# MKL17Z644 register map
Vendor: Freescale Semiconductor, Inc.; Series: Kinetis_L; File version: 1.6
CPU: CM0PLUS r0p0, little endian, no MPU, no FPU, VTOR, 2 interrupt priority bits
Registers are 32-bit, read-write, reset 0x0 unless marked. A register's access mark holds for its fields unless they carry their own. Offsets are from the block's base; [hi:lo] are bit positions; {n}, {i} and the like mark numbered series; 'fields as' and 'values as' point back to an identical list.

## RFSYS — System register file
Base 0x40041000; register names take the prefix RFSYS_
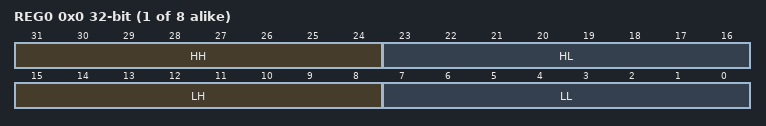
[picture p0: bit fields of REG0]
{0x0+4i} REG{i} (i=0..7) — Register file register
  [31:24] HH, [23:16] HL, [15:8] LH, [7:0] LL

## PORTA — Pin Control and Interrupts
Base 0x40049000; register names take the prefix PORTA_
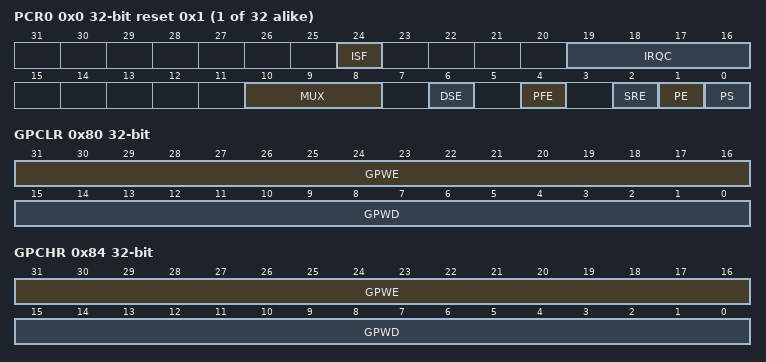
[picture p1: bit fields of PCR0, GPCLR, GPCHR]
{0x0+4i} PCR{i} (i=0..31) reset 0x1 — Pin Control Register n
  [24] ISF — Interrupt Status Flag
    0=Configured interrupt is not detected; 1=Configured interrupt is detected. If the pin is configured to generate a DMA request, then the corresponding flag will be cleared automatically at the completion of the requested DMA transfer. Otherwise, the flag remains set until a logic 1 is written to the flag. If the pin is configured for a level sensitive interrupt and the pin remains asserted, then the flag is set again immediately after it is cleared.
  [19:16] IRQC — Interrupt Configuration
    0=Flag is disabled; 1=Flag and DMA request on rising edge; 2=Flag and DMA request on falling edge; 3=Flag and DMA request on either edge; 8=Flag and Interrupt when logic 0; 9=Flag and Interrupt on rising-edge; 10=Flag and Interrupt on falling-edge; 11=Flag and Interrupt on either edge; 12=Flag and Interrupt when logic 1
  [10:8] MUX — Pin Mux Control
    0=Pin disabled (analog); 1=Alternative 1 (GPIO); {v}=Alternative {v} (chip-specific) (v=2..7)
  [6] DSE — Drive Strength Enable
    0=Low drive strength is configured on the corresponding pin, if pin is configured as a digital output; 1=High drive strength is configured on the corresponding pin, if pin is configured as a digital output
  [4] PFE — Passive Filter Enable
    0=Passive input filter is disabled on the corresponding pin; 1=Passive input filter is enabled on the corresponding pin, if the pin is configured as a digital input. Refer to the device data sheet for filter characteristics.
  [2] SRE — Slew Rate Enable
    0=Fast slew rate is configured on the corresponding pin, if the pin is configured as a digital output; 1=Slow slew rate is configured on the corresponding pin, if the pin is configured as a digital output
  [1] PE — Pull Enable
    0=Internal pullup or pulldown resistor is not enabled on the corresponding pin; 1=Internal pullup or pulldown resistor is enabled on the corresponding pin, if the pin is configured as a digital input
  [0] PS — Pull Select
    0=Internal pulldown resistor is enabled on the corresponding pin, if the corresponding PE field is set; 1=Internal pullup resistor is enabled on the corresponding pin, if the corresponding PE field is set
0x80 GPCLR wo — Global Pin Control Low Register
  [31:16] GPWE — Global Pin Write Enable
    0=Corresponding Pin Control Register is not updated with the value in GPWD; 1=Corresponding Pin Control Register is updated with the value in GPWD
  [15:0] GPWD — Global Pin Write Data
0x84 GPCHR wo — Global Pin Control High Register
  fields as GPCLR
0xA0 ISFR — Interrupt Status Flag Register
  [31:0] ISF — Interrupt Status Flag
    values as PCR0.ISF

## PORTB — Pin Control and Interrupts
Base 0x4004A000; register names take the prefix PORTB_
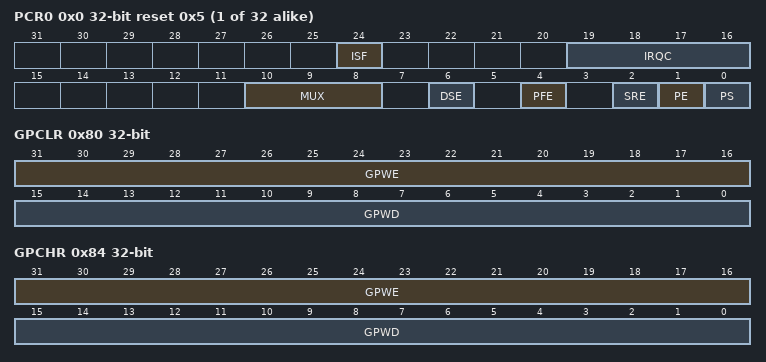
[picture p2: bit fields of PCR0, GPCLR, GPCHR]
{0x0+4i} PCR{i} (i=0..31) reset 0x5 — Pin Control Register n
  [24] ISF — Interrupt Status Flag
    0=Configured interrupt is not detected; 1=Configured interrupt is detected. If the pin is configured to generate a DMA request, then the corresponding flag will be cleared automatically at the completion of the requested DMA transfer. Otherwise, the flag remains set until a logic 1 is written to the flag. If the pin is configured for a level sensitive interrupt and the pin remains asserted, then the flag is set again immediately after it is cleared.
  [19:16] IRQC — Interrupt Configuration
    0=Flag is disabled; 1=Flag and DMA request on rising edge; 2=Flag and DMA request on falling edge; 3=Flag and DMA request on either edge; 8=Flag and Interrupt when logic 0; 9=Flag and Interrupt on rising-edge; 10=Flag and Interrupt on falling-edge; 11=Flag and Interrupt on either edge; 12=Flag and Interrupt when logic 1
  [10:8] MUX — Pin Mux Control
    0=Pin disabled (analog); 1=Alternative 1 (GPIO); {v}=Alternative {v} (chip-specific) (v=2..7)
  [6] DSE — Drive Strength Enable
    0=Low drive strength is configured on the corresponding pin, if pin is configured as a digital output; 1=High drive strength is configured on the corresponding pin, if pin is configured as a digital output
  [4] PFE — Passive Filter Enable
    0=Passive input filter is disabled on the corresponding pin; 1=Passive input filter is enabled on the corresponding pin, if the pin is configured as a digital input. Refer to the device data sheet for filter characteristics.
  [2] SRE — Slew Rate Enable
    0=Fast slew rate is configured on the corresponding pin, if the pin is configured as a digital output; 1=Slow slew rate is configured on the corresponding pin, if the pin is configured as a digital output
  [1] PE — Pull Enable
    0=Internal pullup or pulldown resistor is not enabled on the corresponding pin; 1=Internal pullup or pulldown resistor is enabled on the corresponding pin, if the pin is configured as a digital input
  [0] PS — Pull Select
    0=Internal pulldown resistor is enabled on the corresponding pin, if the corresponding PE field is set; 1=Internal pullup resistor is enabled on the corresponding pin, if the corresponding PE field is set
0x80 GPCLR wo — Global Pin Control Low Register
  [31:16] GPWE — Global Pin Write Enable
    0=Corresponding Pin Control Register is not updated with the value in GPWD; 1=Corresponding Pin Control Register is updated with the value in GPWD
  [15:0] GPWD — Global Pin Write Data
0x84 GPCHR wo — Global Pin Control High Register
  fields as GPCLR
0xA0 ISFR — Interrupt Status Flag Register
  [31:0] ISF — Interrupt Status Flag
    values as PCR0.ISF

## PORTC — Pin Control and Interrupts
Base 0x4004B000; register names take the prefix PORTC_
Registers as PORTB.

## PORTD — Pin Control and Interrupts
Base 0x4004C000; register names take the prefix PORTD_
Registers as PORTB.

## PORTE — Pin Control and Interrupts
Base 0x4004D000; register names take the prefix PORTE_
Registers as PORTB.

## Notices in the file
Redistribution and use in source and binary forms, with or without modification,
are permitted provided that the following conditions are met:
o Redistributions of source code must retain the above copyright notice, this list
of conditions and the following disclaimer.
o Redistributions in binary form must reproduce the above copyright notice, this
list of conditions and the following disclaimer in the documentation and/or
other materials provided with the distribution.
o Neither the name of Freescale Semiconductor, Inc. nor the names of its
contributors may be used to endorse or promote products derived from this
software without specific prior written permission.
THIS SOFTWARE IS PROVIDED BY THE COPYRIGHT HOLDERS AND CONTRIBUTORS "AS IS" AND
ANY EXPRESS OR IMPLIED WARRANTIES, INCLUDING, BUT NOT LIMITED TO, THE IMPLIED
WARRANTIES OF MERCHANTABILITY AND FITNESS FOR A PARTICULAR PURPOSE ARE
DISCLAIMED. IN NO EVENT SHALL THE COPYRIGHT HOLDER OR CONTRIBUTORS BE LIABLE FOR
ANY DIRECT, INDIRECT, INCIDENTAL, SPECIAL, EXEMPLARY, OR CONSEQUENTIAL DAMAGES
(INCLUDING, BUT NOT LIMITED TO, PROCUREMENT OF SUBSTITUTE GOODS OR SERVICES;
LOSS OF USE, DATA, OR PROFITS; OR BUSINESS INTERRUPTION) HOWEVER CAUSED AND ON
ANY THEORY OF LIABILITY, WHETHER IN CONTRACT, STRICT LIABILITY, OR TORT
(INCLUDING NEGLIGENCE OR OTHERWISE) ARISING IN ANY WAY OUT OF THE USE OF THIS
SOFTWARE, EVEN IF ADVISED OF THE POSSIBILITY OF SUCH DAMAGE.
